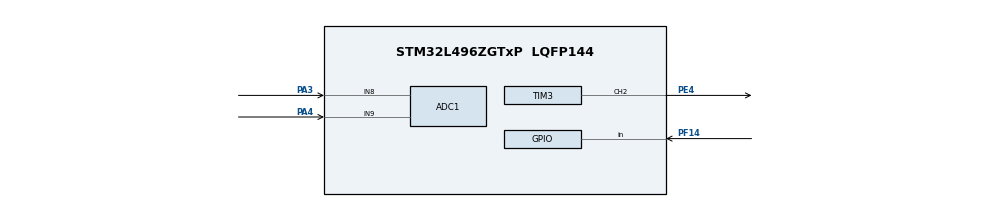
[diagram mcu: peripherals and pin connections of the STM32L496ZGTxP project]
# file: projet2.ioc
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ADC1.Channel-0\#ChannelRegularConversion=ADC_CHANNEL_8
ADC1.NbrOfConversionFlag=1
ADC1.OffsetNumber-0\#ChannelRegularConversion=ADC_OFFSET_NONE
ADC1.Rank-0\#ChannelRegularConversion=1
ADC1.SamplingTime-0\#ChannelRegularConversion=ADC_SAMPLETIME_2CYCLES_5
ADC1.SingleDiff-0\#ChannelRegularConversion=ADC_DIFFERENTIAL_ENDED
ADC1.master=1
Mcu.Family=STM32L4
Mcu.Name=STM32L496ZGTxP
Mcu.Package=LQFP144
NVIC.PriorityGroup=NVIC_PRIORITYGROUP_4
PA3.Signal=ADCx_IN8
PA4.Signal=ADCx_IN9
PE4.Signal=S_TIM3_CH2
PF14.GPIO_PuPd=GPIO_PULLDOWN
PF14.Signal=GPIO_Input
ProjectManager.HeapSize=0x200
ProjectManager.StackSize=0x400
ProjectManager.TargetToolchain=STM32CubeIDE
RCC.HSE_VALUE=8000000
RCC.HSI48_VALUE=48000000
RCC.HSI_VALUE=16000000
RCC.LSE_VALUE=32768
RCC.MSI_VALUE=4000000
RCC.VCOOutputFreq_Value=32000000
SH.ADCx_IN8.0=ADC1_IN8,IN8-Differential
SH.ADCx_IN9.0=ADC1_IN9,IN8-Differential
SH.S_TIM3_CH2.0=TIM3_CH2,PWM Generation2 CH2
TIM3.Channel-PWM\ Generation2\ CH2=TIM_CHANNEL_2
TIM3.Prescaler=139
board=custom

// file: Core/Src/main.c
/* USER CODE BEGIN Header */
/**
  ******************************************************************************
  * @file           : main.c
  * @brief          : Main program body
  ******************************************************************************
  * @attention
  *
  * <h2><center>&copy; Copyright (c) 2026 STMicroelectronics.
  * All rights reserved.</center></h2>
  *
  * This software component is licensed by ST under BSD 3-Clause license,
  * the "License"; You may not use this file except in compliance with the
  * License. You may obtain a copy of the License at:
  *                        opensource.org/licenses/BSD-3-Clause
  *
  ******************************************************************************
  */
/* USER CODE END Header */
#include "main.h"

/* USER CODE BEGIN Includes */
#include <string.h>
#include <stdio.h>

/* Private includes ----------------------------------------------------------*/
/* USER CODE BEGIN Includes */

/* USER CODE END Includes */

ADC_HandleTypeDef hadc1;

TIM_HandleTypeDef htim3;

void SystemClock_Config(void);
static void MX_GPIO_Init(void);
static void MX_TIM3_Init(void);
static void MX_ADC1_Init(void);

int main(void)
{

  /* MCU Configuration--------------------------------------------------------*/

  /* Reset of all peripherals, Initializes the Flash interface and the Systick. */
  HAL_Init();

  /* Configure the system clock */
  SystemClock_Config();

  /* Initialize all configured peripherals */
  MX_GPIO_Init();
  MX_TIM3_Init();
  MX_ADC1_Init();
  /* USER CODE BEGIN 2 */

  HAL_TIM_PWM_Start(&htim3, TIM_CHANNEL_2);

  int position = 50;
  int direction = 1;
  static uint8_t last_raw = GPIO_PIN_RESET;

  while (1)
  {
      /* ================= CAPTEUR DE LUMIÈRE ================= */

      /* ================= CAPTEUR DE PRÉSENCE ================= */
      uint8_t raw = HAL_GPIO_ReadPin(GPIOF, GPIO_PIN_14);

      HAL_GPIO_WritePin(GPIOB, GPIO_PIN_7,
                        (raw == GPIO_PIN_SET) ? GPIO_PIN_SET : GPIO_PIN_RESET);

      /* ---- ARRIVÉE DE PRÉSENCE : UNE SEULE FOIS ---- */
      if ((raw == GPIO_PIN_SET) && (last_raw == GPIO_PIN_RESET))
      {
          printf("Presence detectee\r\n");
          for (int i = 0; i < 5; i++)
          {
              __HAL_TIM_SET_COMPARE(&htim3, TIM_CHANNEL_2, 60);
              HAL_Delay(80);
              __HAL_TIM_SET_COMPARE(&htim3, TIM_CHANNEL_2, 90);
              HAL_Delay(80);
          }
      }

      /* ---- ABSENCE : MOUVEMENT CONTINU ---- */
      if (raw == GPIO_PIN_RESET)
      {
          position += direction;

          if (position >= 100) { position = 100; direction = -1; }
          if (position <= 50)  { position = 50;  direction =  1; }

          __HAL_TIM_SET_COMPARE(&htim3, TIM_CHANNEL_2, position);
          HAL_Delay(30);
      }

      last_raw = raw;
      HAL_Delay(100);
  }
}

void SystemClock_Config(void)
{
  RCC_OscInitTypeDef RCC_OscInitStruct = {0};
  RCC_ClkInitTypeDef RCC_ClkInitStruct = {0};
  RCC_PeriphCLKInitTypeDef PeriphClkInit = {0};

  /** Initializes the RCC Oscillators according to the specified parameters
  * in the RCC_OscInitTypeDef structure.
  */
  RCC_OscInitStruct.OscillatorType = RCC_OSCILLATORTYPE_MSI;
  RCC_OscInitStruct.MSIState = RCC_MSI_ON;
  RCC_OscInitStruct.MSICalibrationValue = 0;
  RCC_OscInitStruct.MSIClockRange = RCC_MSIRANGE_6;
  RCC_OscInitStruct.PLL.PLLState = RCC_PLL_NONE;
  if (HAL_RCC_OscConfig(&RCC_OscInitStruct) != HAL_OK)
  {
    Error_Handler();
  }
  /** Initializes the CPU, AHB and APB buses clocks
  */
  RCC_ClkInitStruct.ClockType = RCC_CLOCKTYPE_HCLK|RCC_CLOCKTYPE_SYSCLK
                              |RCC_CLOCKTYPE_PCLK1|RCC_CLOCKTYPE_PCLK2;
  RCC_ClkInitStruct.SYSCLKSource = RCC_SYSCLKSOURCE_MSI;
  RCC_ClkInitStruct.AHBCLKDivider = RCC_SYSCLK_DIV1;
  RCC_ClkInitStruct.APB1CLKDivider = RCC_HCLK_DIV1;
  RCC_ClkInitStruct.APB2CLKDivider = RCC_HCLK_DIV1;

  if (HAL_RCC_ClockConfig(&RCC_ClkInitStruct, FLASH_LATENCY_0) != HAL_OK)
  {
    Error_Handler();
  }
  PeriphClkInit.PeriphClockSelection = RCC_PERIPHCLK_ADC;
  PeriphClkInit.AdcClockSelection = RCC_ADCCLKSOURCE_PLLSAI1;
  PeriphClkInit.PLLSAI1.PLLSAI1Source = RCC_PLLSOURCE_MSI;
  PeriphClkInit.PLLSAI1.PLLSAI1M = 1;
  PeriphClkInit.PLLSAI1.PLLSAI1N = 8;
  PeriphClkInit.PLLSAI1.PLLSAI1P = RCC_PLLP_DIV2;
  PeriphClkInit.PLLSAI1.PLLSAI1Q = RCC_PLLQ_DIV2;
  PeriphClkInit.PLLSAI1.PLLSAI1R = RCC_PLLR_DIV2;
  PeriphClkInit.PLLSAI1.PLLSAI1ClockOut = RCC_PLLSAI1_ADC1CLK;
  if (HAL_RCCEx_PeriphCLKConfig(&PeriphClkInit) != HAL_OK)
  {
    Error_Handler();
  }
  /** Configure the main internal regulator output voltage
  */
  if (HAL_PWREx_ControlVoltageScaling(PWR_REGULATOR_VOLTAGE_SCALE1) != HAL_OK)
  {
    Error_Handler();
  }
}

static void MX_ADC1_Init(void)
{

  ADC_MultiModeTypeDef multimode = {0};
  ADC_ChannelConfTypeDef sConfig = {0};

  /** Common config
  */
  hadc1.Instance = ADC1;
  hadc1.Init.ClockPrescaler = ADC_CLOCK_ASYNC_DIV1;
  hadc1.Init.Resolution = ADC_RESOLUTION_12B;
  hadc1.Init.DataAlign = ADC_DATAALIGN_RIGHT;
  hadc1.Init.ScanConvMode = ADC_SCAN_DISABLE;
  hadc1.Init.EOCSelection = ADC_EOC_SINGLE_CONV;
  hadc1.Init.LowPowerAutoWait = DISABLE;
  hadc1.Init.ContinuousConvMode = DISABLE;
  hadc1.Init.NbrOfConversion = 1;
  hadc1.Init.DiscontinuousConvMode = DISABLE;
  hadc1.Init.ExternalTrigConv = ADC_SOFTWARE_START;
  hadc1.Init.ExternalTrigConvEdge = ADC_EXTERNALTRIGCONVEDGE_NONE;
  hadc1.Init.DMAContinuousRequests = DISABLE;
  hadc1.Init.Overrun = ADC_OVR_DATA_PRESERVED;
  hadc1.Init.OversamplingMode = DISABLE;
  if (HAL_ADC_Init(&hadc1) != HAL_OK)
  {
    Error_Handler();
  }
  /** Configure the ADC multi-mode
  */
  multimode.Mode = ADC_MODE_INDEPENDENT;
  if (HAL_ADCEx_MultiModeConfigChannel(&hadc1, &multimode) != HAL_OK)
  {
    Error_Handler();
  }
  /** Configure Regular Channel
  */
  sConfig.Channel = ADC_CHANNEL_8;
  sConfig.Rank = ADC_REGULAR_RANK_1;
  sConfig.SamplingTime = ADC_SAMPLETIME_2CYCLES_5;
  sConfig.SingleDiff = ADC_DIFFERENTIAL_ENDED;
  sConfig.OffsetNumber = ADC_OFFSET_NONE;
  sConfig.Offset = 0;
  if (HAL_ADC_ConfigChannel(&hadc1, &sConfig) != HAL_OK)
  {
    Error_Handler();
  }

}

static void MX_TIM3_Init(void)
{

  TIM_MasterConfigTypeDef sMasterConfig = {0};
  TIM_OC_InitTypeDef sConfigOC = {0};

  htim3.Instance = TIM3;
  htim3.Init.Prescaler = 139;
  htim3.Init.CounterMode = TIM_COUNTERMODE_UP;
  htim3.Init.Period = 65535;
  htim3.Init.ClockDivision = TIM_CLOCKDIVISION_DIV1;
  htim3.Init.AutoReloadPreload = TIM_AUTORELOAD_PRELOAD_DISABLE;
  if (HAL_TIM_PWM_Init(&htim3) != HAL_OK)
  {
    Error_Handler();
  }
  sMasterConfig.MasterOutputTrigger = TIM_TRGO_RESET;
  sMasterConfig.MasterSlaveMode = TIM_MASTERSLAVEMODE_DISABLE;
  if (HAL_TIMEx_MasterConfigSynchronization(&htim3, &sMasterConfig) != HAL_OK)
  {
    Error_Handler();
  }
  sConfigOC.OCMode = TIM_OCMODE_PWM1;
  sConfigOC.Pulse = 0;
  sConfigOC.OCPolarity = TIM_OCPOLARITY_HIGH;
  sConfigOC.OCFastMode = TIM_OCFAST_DISABLE;
  if (HAL_TIM_PWM_ConfigChannel(&htim3, &sConfigOC, TIM_CHANNEL_2) != HAL_OK)
  {
    Error_Handler();
  }
  HAL_TIM_MspPostInit(&htim3);

}

static void MX_GPIO_Init(void)
{
  GPIO_InitTypeDef GPIO_InitStruct = {0};

  /* GPIO Ports Clock Enable */
  __HAL_RCC_GPIOE_CLK_ENABLE();
  __HAL_RCC_GPIOA_CLK_ENABLE();
  __HAL_RCC_GPIOF_CLK_ENABLE();

  /*Configure GPIO pin : PF14 */
  GPIO_InitStruct.Pin = GPIO_PIN_14;
  GPIO_InitStruct.Mode = GPIO_MODE_INPUT;
  GPIO_InitStruct.Pull = GPIO_PULLDOWN;
  HAL_GPIO_Init(GPIOF, &GPIO_InitStruct);

}

void Error_Handler(void)
{
  __disable_irq();
  while (1)
  {
  }
}

/************************ (C) COPYRIGHT STMicroelectronics *****END OF FILE****/
